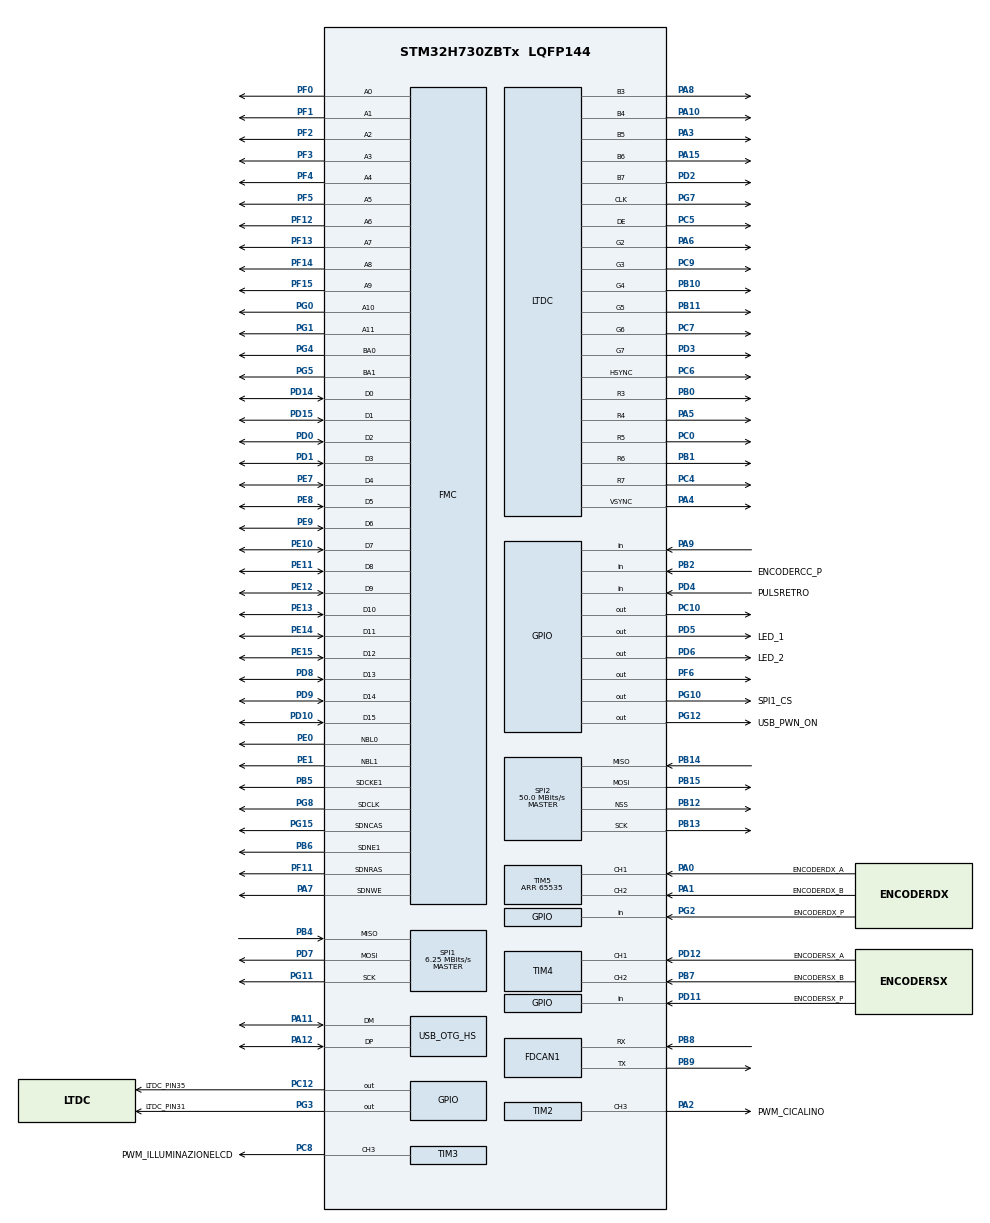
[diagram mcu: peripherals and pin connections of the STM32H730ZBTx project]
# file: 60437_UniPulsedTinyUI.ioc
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CORTEX_M7.AccessPermission-Cortex_Memory_Protection_Unit_Region1_Settings=MPU_REGION_FULL_ACCESS
CORTEX_M7.AccessPermission-Cortex_Memory_Protection_Unit_Region2_Settings=MPU_REGION_FULL_ACCESS
CORTEX_M7.BaseAddress-Cortex_Memory_Protection_Unit_Region1_Settings=0x90000000
CORTEX_M7.BaseAddress-Cortex_Memory_Protection_Unit_Region2_Settings=0xd0000000
CORTEX_M7.CPU_DCache=Enabled
CORTEX_M7.CPU_ICache=Enabled
CORTEX_M7.DisableExec-Cortex_Memory_Protection_Unit_Region1_Settings=MPU_INSTRUCTION_ACCESS_ENABLE
CORTEX_M7.DisableExec-Cortex_Memory_Protection_Unit_Region2_Settings=MPU_INSTRUCTION_ACCESS_DISABLE
CORTEX_M7.Enable-Cortex_Memory_Protection_Unit_Region0_Settings=__NULL
CORTEX_M7.Enable-Cortex_Memory_Protection_Unit_Region1_Settings=MPU_REGION_ENABLE
CORTEX_M7.Enable-Cortex_Memory_Protection_Unit_Region2_Settings=MPU_REGION_ENABLE
CORTEX_M7.IsBufferable-Cortex_Memory_Protection_Unit_Region1_Settings=MPU_ACCESS_BUFFERABLE
CORTEX_M7.IsBufferable-Cortex_Memory_Protection_Unit_Region2_Settings=MPU_ACCESS_BUFFERABLE
CORTEX_M7.IsCacheable-Cortex_Memory_Protection_Unit_Region1_Settings=MPU_ACCESS_CACHEABLE
CORTEX_M7.IsCacheable-Cortex_Memory_Protection_Unit_Region2_Settings=MPU_ACCESS_CACHEABLE
CORTEX_M7.IsShareable-Cortex_Memory_Protection_Unit_Region1_Settings=MPU_ACCESS_SHAREABLE
CORTEX_M7.MPU_Control=MPU_PRIVILEGED_DEFAULT
CORTEX_M7.Size-Cortex_Memory_Protection_Unit_Region1_Settings=MPU_REGION_SIZE_32MB
CORTEX_M7.Size-Cortex_Memory_Protection_Unit_Region2_Settings=MPU_REGION_SIZE_8MB
CORTEX_M7.default_mode_Activation=0
DMA2D.ColorMode=DMA2D_OUTPUT_RGB565
FATFS._FS_LOCK=2
FATFS._FS_NORTC=0
FATFS._USE_FIND=1
FATFS._USE_LFN=3
FATFS._USE_MKFS=0
FDCAN1.AutoRetransmission=ENABLE
FDCAN1.CalculateBaudRateNominal=125000
FDCAN1.CalculateTimeBitNominal=8000
FDCAN1.CalculateTimeQuantumNominal=500.0
FDCAN1.FrameFormat=FDCAN_FRAME_CLASSIC
FDCAN1.NominalPrescaler=50
FDCAN1.NominalTimeSeg1=13
FDCAN1.RxBuffersNbr=16
FDCAN1.RxFifo0ElmtsNbr=16
FDCAN1.RxFifo1ElmtsNbr=0
FDCAN1.StdFiltersNbr=1
FDCAN1.TxFifoQueueElmtsNbr=16
FMC.CASLatency2=FMC_SDRAM_CAS_LATENCY_3
FMC.ExitSelfRefreshDelay2=14
FMC.LoadToActiveDelay2=2
FMC.RCDDelay2=3
FMC.RPDelay2=3
FMC.ReadBurst2=FMC_SDRAM_RBURST_ENABLE
FMC.ReadPipeDelay2=FMC_SDRAM_RPIPE_DELAY_1
FMC.RowCycleDelay2=11
FMC.SDClockPeriod2=FMC_SDRAM_CLOCK_PERIOD_2
FMC.SelfRefreshTime2=8
FMC.WriteRecoveryTime2=5
FREERTOS.Tasks01=defaultTask,24,512,StartDefaultTask,Default,NULL,Dynamic,NULL,NULL
FREERTOS.configCHECK_FOR_STACK_OVERFLOW=2
FREERTOS.configENABLE_FPU=1
FREERTOS.configQUEUE_REGISTRY_SIZE=16
FREERTOS.configRECORD_STACK_HIGH_ADDRESS=1
FREERTOS.configTIMER_QUEUE_LENGTH=15
FREERTOS.configTOTAL_HEAP_SIZE=120000
FREERTOS.configUSE_APPLICATION_TASK_TAG=1
FREERTOS.configUSE_IDLE_HOOK=1
FREERTOS.configUSE_NEWLIB_REENTRANT=1
LTDC.ActiveH=272
LTDC.ActiveW=480
LTDC.Alpha_L0=255
LTDC.HBP=88
LTDC.HFP=40
LTDC.HSync=48
LTDC.ImageHeight_L0=272
LTDC.ImageWidth_L0=480
LTDC.Layers=0
LTDC.PixelFormat_L0=LTDC_PIXEL_FORMAT_RGB565
LTDC.VBP=32
LTDC.VFP=13
LTDC.VSync=3
LTDC.WindowX1_L0=480
LTDC.WindowY1_L0=272
Mcu.Family=STM32H7
Mcu.Name=STM32H730ZBTx
Mcu.Package=LQFP144
NVIC.DMA2D_IRQn=true\:5\:0\:false\:false\:true\:true\:true\:true\:true
NVIC.FDCAN1_IT0_IRQn=true\:5\:0\:false\:false\:true\:true\:true\:true\:true
NVIC.FDCAN1_IT1_IRQn=true\:5\:0\:false\:false\:true\:true\:true\:true\:true
NVIC.LTDC_IRQn=true\:5\:0\:false\:false\:true\:true\:true\:true\:true
NVIC.OTG_HS_IRQn=true\:5\:0\:false\:false\:true\:true\:false\:true\:true
NVIC.PriorityGroup=NVIC_PRIORITYGROUP_4
NVIC.TIM6_DAC_IRQn=true\:15\:0\:false\:false\:true\:false\:false\:true\:true
NVIC.TimeBase=TIM6_DAC_IRQn
NVIC.TimeBaseIP=TIM6
PA0.GPIO_Label=ENCODERDX_A
PA0.Signal=S_TIM5_CH1
PA1.GPIO_Label=ENCODERDX_B
PA1.Signal=S_TIM5_CH2
PA10.Mode=RGB565
PA10.Signal=LTDC_B4
PA11.Mode=Host_FS
PA11.Signal=USB_OTG_HS_DM
PA12.Mode=Host_FS
PA12.Signal=USB_OTG_HS_DP
PA13(JTMS/SWDIO).Mode=Trace_Asynchronous_SW
PA13(JTMS/SWDIO).Signal=DEBUG_JTMS-SWDIO
PA14(JTCK/SWCLK).Mode=Trace_Asynchronous_SW
PA14(JTCK/SWCLK).Signal=DEBUG_JTCK-SWCLK
PA15(JTDI).Mode=RGB565
PA15(JTDI).Signal=LTDC_B6
PA2.GPIO_Label=PWM_CICALINO
PA2.Signal=S_TIM2_CH3
PA3.Mode=RGB565
PA3.Signal=LTDC_B5
PA4.Mode=RGB565
PA4.Signal=LTDC_VSYNC
PA5.Mode=RGB565
PA5.Signal=LTDC_R4
PA6.Mode=RGB565
PA6.Signal=LTDC_G2
PA7.Signal=FMC_SDNWE
PA8.Mode=RGB565
PA8.Signal=LTDC_B3
PA9.Signal=GPIO_Input
PB0.Mode=RGB565
PB0.Signal=LTDC_R3
PB1.Mode=RGB565
PB1.Signal=LTDC_R6
PB10.Mode=RGB565
PB10.Signal=LTDC_G4
PB11.Mode=RGB565
PB11.Signal=LTDC_G5
PB12.Mode=NSS_Signal_Hard_Output
PB12.Signal=SPI2_NSS
PB13.Mode=Full_Duplex_Master
PB13.Signal=SPI2_SCK
PB14.Mode=Full_Duplex_Master
PB14.Signal=SPI2_MISO
PB15.Mode=Full_Duplex_Master
PB15.Signal=SPI2_MOSI
PB2.GPIO_Label=ENCODERCC_P
PB2.Signal=GPIO_Input
PB3(JTDO/TRACESWO).Mode=Trace_Asynchronous_SW
PB3(JTDO/TRACESWO).Signal=DEBUG_JTDO-SWO
PB4(NJTRST).Mode=Full_Duplex_Master
PB4(NJTRST).Signal=SPI1_MISO
PB5.Mode=SdramChipSelect2_2
PB5.Signal=FMC_SDCKE1
PB6.Mode=SdramChipSelect2_2
PB6.Signal=FMC_SDNE1
PB7.GPIO_Label=ENCODERSX_B
PB7.Signal=S_TIM4_CH2
PB8.Mode=FDCAN_Activate
PB8.Signal=FDCAN1_RX
PB9.Mode=FDCAN_Activate
PB9.Signal=FDCAN1_TX
PC0.Mode=RGB565
PC0.Signal=LTDC_R5
PC10.Signal=GPIO_Output
PC12.GPIO_Label=LTDC_PIN35
PC12.Signal=GPIO_Output
PC14-OSC32_IN.Mode=LSE-External-Oscillator
PC14-OSC32_IN.Signal=RCC_OSC32_IN
PC15-OSC32_OUT.Mode=LSE-External-Oscillator
PC15-OSC32_OUT.Signal=RCC_OSC32_OUT
PC4.Mode=RGB565
PC4.Signal=LTDC_R7
PC5.Mode=RGB565
PC5.Signal=LTDC_DE
PC6.Mode=RGB565
PC6.Signal=LTDC_HSYNC
PC7.Mode=RGB565
PC7.Signal=LTDC_G6
PC8.GPIO_Label=PWM_ILLUMINAZIONELCD
PC8.Signal=S_TIM3_CH3
PC9.Mode=RGB565
PC9.Signal=LTDC_G3
PD0.Signal=FMC_D2_DA2
PD1.Signal=FMC_D3_DA3
PD10.Signal=FMC_D15_DA15
PD11.GPIO_Label=ENCODERSX_P
PD11.Signal=GPIO_Input
PD12.GPIO_Label=ENCODERSX_A
PD12.Signal=S_TIM4_CH1
PD14.Signal=FMC_D0_DA0
PD15.Signal=FMC_D1_DA1
PD2.Mode=RGB565
PD2.Signal=LTDC_B7
PD3.Mode=RGB565
PD3.Signal=LTDC_G7
PD4.GPIO_Label=PULSRETRO
PD4.Signal=GPIO_Input
PD5.GPIO_Label=LED_1
PD5.Signal=GPIO_Output
PD6.GPIO_Label=LED_2
PD6.Signal=GPIO_Output
PD7.Mode=Full_Duplex_Master
PD7.Signal=SPI1_MOSI
PD8.Signal=FMC_D13_DA13
PD9.Signal=FMC_D14_DA14
PE0.Signal=FMC_NBL0
PE1.Signal=FMC_NBL1
PE10.Signal=FMC_D7_DA7
PE11.Signal=FMC_D8_DA8
PE12.Signal=FMC_D9_DA9
PE13.Signal=FMC_D10_DA10
PE14.Signal=FMC_D11_DA11
PE15.Signal=FMC_D12_DA12
PE7.Signal=FMC_D4_DA4
PE8.Signal=FMC_D5_DA5
PE9.Signal=FMC_D6_DA6
PF0.Signal=FMC_A0
PF1.Signal=FMC_A1
PF11.Signal=FMC_SDNRAS
PF12.Signal=FMC_A6
PF13.Signal=FMC_A7
PF14.Signal=FMC_A8
PF15.Signal=FMC_A9
PF2.Signal=FMC_A2
PF3.Signal=FMC_A3
PF4.Signal=FMC_A4
PF5.Signal=FMC_A5
PF6.Signal=GPIO_Output
PF7.Signal=OCTOSPIM_P1_IO2
PG0.Signal=FMC_A10
PG1.Signal=FMC_A11
PG10.GPIO_Label=SPI1_CS
PG10.GPIO_ModeDefaultOutputPP=GPIO_MODE_OUTPUT_OD
PG10.GPIO_PuPd=GPIO_NOPULL
PG10.PinState=GPIO_PIN_SET
PG10.Signal=GPIO_Output
PG11.Mode=Full_Duplex_Master
PG11.Signal=SPI1_SCK
PG12.GPIO_Label=USB_PWN_ON
PG12.GPIO_ModeDefaultOutputPP=GPIO_MODE_OUTPUT_OD
PG12.GPIO_PuPd=GPIO_NOPULL
PG12.PinState=GPIO_PIN_SET
PG12.Signal=GPIO_Output
PG15.Signal=FMC_SDNCAS
PG2.GPIO_Label=ENCODERDX_P
PG2.Signal=GPIO_Input
PG3.GPIO_Label=LTDC_PIN31
PG3.Signal=GPIO_Output
PG4.Signal=FMC_A14_BA0
PG5.Signal=FMC_A15_BA1
PG7.Mode=RGB565
PG7.Signal=LTDC_CLK
PG8.Signal=FMC_SDCLK
PH0-OSC_IN.Mode=HSE-External-Oscillator
PH0-OSC_IN.Signal=RCC_OSC_IN
PH1-OSC_OUT.Mode=HSE-External-Oscillator
PH1-OSC_OUT.Signal=RCC_OSC_OUT
ProjectManager.HeapSize=0x00
ProjectManager.StackSize=0x4000
ProjectManager.TargetToolchain=STM32CubeIDE
RCC.ADCFreq_Value=100000000
RCC.APB1Freq_Value=137500000
RCC.APB2Freq_Value=137500000
RCC.APB3Freq_Value=137500000
RCC.APB4Freq_Value=137500000
RCC.CortexFreq_Value=550000000
RCC.D1PPRE=RCC_APB3_DIV2
RCC.D2PPRE1=RCC_APB1_DIV2
RCC.D2PPRE2=RCC_APB2_DIV2
RCC.D3PPRE=RCC_APB4_DIV2
RCC.DIVM1=8
RCC.DIVM2=8
RCC.DIVM3=16
RCC.DIVN1=275
RCC.DIVN2=100
RCC.DIVN3=30
RCC.DIVP1=1
RCC.DIVR2=1
RCC.DIVR3=3
RCC.FDCANCLockSelection=RCC_FDCANCLKSOURCE_PLL2
RCC.HCLKFreq_Value=275000000
RCC.HPRE=RCC_HCLK_DIV2
RCC.HSE_VALUE=16000000
RCC.PLLSourceVirtual=RCC_PLLSOURCE_HSE
RCC.RTCClockSelection=RCC_RTCCLKSOURCE_LSE
RCC.SPI123CLockSelection=RCC_SPI123CLKSOURCE_PLL2
RCC.SYSCLKFreq_VALUE=550000000
RCC.SYSCLKSource=RCC_SYSCLKSOURCE_PLLCLK
RCC.USBCLockSelection=RCC_USBCLKSOURCE_HSI48
RCC.USBFreq_Value=48000000
SH.FMC_A0.0=FMC_A0,12b-sda2
SH.FMC_A1.0=FMC_A1,12b-sda2
SH.FMC_A10.0=FMC_A10,12b-sda2
SH.FMC_A11.0=FMC_A11,12b-sda2
SH.FMC_A14_BA0.0=FMC_BA0,FourSdramBanks2
SH.FMC_A15_BA1.0=FMC_BA1,FourSdramBanks2
SH.FMC_A2.0=FMC_A2,12b-sda2
SH.FMC_A3.0=FMC_A3,12b-sda2
SH.FMC_A4.0=FMC_A4,12b-sda2
SH.FMC_A5.0=FMC_A5,12b-sda2
SH.FMC_A6.0=FMC_A6,12b-sda2
SH.FMC_A7.0=FMC_A7,12b-sda2
SH.FMC_A8.0=FMC_A8,12b-sda2
SH.FMC_A9.0=FMC_A9,12b-sda2
SH.FMC_D0_DA0.0=FMC_D0,sd-16b-d2
SH.FMC_D10_DA10.0=FMC_D10,sd-16b-d2
SH.FMC_D11_DA11.0=FMC_D11,sd-16b-d2
SH.FMC_D12_DA12.0=FMC_D12,sd-16b-d2
SH.FMC_D13_DA13.0=FMC_D13,sd-16b-d2
SH.FMC_D14_DA14.0=FMC_D14,sd-16b-d2
SH.FMC_D15_DA15.0=FMC_D15,sd-16b-d2
SH.FMC_D1_DA1.0=FMC_D1,sd-16b-d2
SH.FMC_D2_DA2.0=FMC_D2,sd-16b-d2
SH.FMC_D3_DA3.0=FMC_D3,sd-16b-d2
SH.FMC_D4_DA4.0=FMC_D4,sd-16b-d2
SH.FMC_D5_DA5.0=FMC_D5,sd-16b-d2
SH.FMC_D6_DA6.0=FMC_D6,sd-16b-d2
SH.FMC_D7_DA7.0=FMC_D7,sd-16b-d2
SH.FMC_D8_DA8.0=FMC_D8,sd-16b-d2
SH.FMC_D9_DA9.0=FMC_D9,sd-16b-d2
SH.FMC_NBL0.0=FMC_NBL0,Sd2ByteEnable2
SH.FMC_NBL1.0=FMC_NBL1,Sd2ByteEnable2
SH.FMC_SDCLK.0=FMC_SDCLK,12b-sda2
SH.FMC_SDNCAS.0=FMC_SDNCAS,12b-sda2
SH.FMC_SDNRAS.0=FMC_SDNRAS,12b-sda2
SH.FMC_SDNWE.0=FMC_SDNWE,12b-sda2
SH.S_TIM2_CH3.0=TIM2_CH3,PWM Generation3 CH3
SH.S_TIM3_CH3.0=TIM3_CH3,PWM Generation3 CH3
SH.S_TIM4_CH1.0=TIM4_CH1,Encoder_Interface
SH.S_TIM4_CH2.0=TIM4_CH2,Encoder_Interface
SH.S_TIM5_CH1.0=TIM5_CH1,Encoder_Interface
SH.S_TIM5_CH2.0=TIM5_CH2,Encoder_Interface
SPI1.BaudRatePrescaler=SPI_BAUDRATEPRESCALER_16
SPI1.CalculateBaudRate=6.25 MBits/s
SPI1.DataSize=SPI_DATASIZE_8BIT
SPI1.Direction=SPI_DIRECTION_2LINES
SPI1.Mode=SPI_MODE_MASTER
SPI1.VirtualType=VM_MASTER
SPI2.BaudRatePrescaler=SPI_BAUDRATEPRESCALER_2
SPI2.CalculateBaudRate=50.0 MBits/s
SPI2.Direction=SPI_DIRECTION_2LINES
SPI2.Mode=SPI_MODE_MASTER
SPI2.VirtualNSS=VM_NSSHARD
SPI2.VirtualType=VM_MASTER
STMicroelectronics.X-CUBE-TOUCHGFX.4.24.1.ApplicationCcGraphicsJjApplication=TouchGFXOoGenerator
STMicroelectronics.X-CUBE-TOUCHGFX.4.24.1.tgfx_address1=0xd0000000
STMicroelectronics.X-CUBE-TOUCHGFX.4.24.1.tgfx_address2=0xd003fc00
STMicroelectronics.X-CUBE-TOUCHGFX.4.24.1.tgfx_buffering_strategy=Double
STMicroelectronics.X-CUBE-TOUCHGFX.4.24.1.tgfx_display_interface=disp_ltdc
STMicroelectronics.X-CUBE-TOUCHGFX.4.24.1.tgfx_hardware_accelerator=dma_2d
STMicroelectronics.X-CUBE-TOUCHGFX.4.24.1.tgfx_location=By Address
STMicroelectronics.X-CUBE-TOUCHGFX.4.24.1.tgfx_vsync=vsync_ltdc
STMicroelectronics.X-CUBE-TOUCHGFX.4.24.1_IsPackSelfContextualization=true
TIM2.Channel-PWM\ Generation3\ CH3=TIM_CHANNEL_3
TIM2.Period=1000
TIM2.Prescaler=68
TIM2.Pulse-PWM\ Generation3\ CH3=500
TIM3.AutoReloadPreload=TIM_AUTORELOAD_PRELOAD_ENABLE
TIM3.Channel-PWM\ Generation3\ CH3=TIM_CHANNEL_3
TIM3.ClockDivision=TIM_CLOCKDIVISION_DIV4
TIM3.OCFastMode_PWM-PWM\ Generation3\ CH3=TIM_OCFAST_DISABLE
TIM3.Period=1000
TIM3.Prescaler=5
TIM3.Pulse-PWM\ Generation3\ CH3=5000
TIM4.IC1Polarity=TIM_ICPOLARITY_RISING
TIM4.IC2Polarity=TIM_ICPOLARITY_RISING
TIM5.IC1Polarity=TIM_ICPOLARITY_RISING
TIM5.IC2Polarity=TIM_ICPOLARITY_RISING
TIM5.Period=65535
USB_HOST.BSP.number=1
USB_HOST.USBH_DEBUG_LEVEL=3
USB_HOST.USBH_HandleTypeDef=hUsbHostHS
USB_HOST.USBH_PROCESS_STACK_SIZE=512
USB_HOST.VirtualModeHS=Msc
USB_HOST0.BSP.STBoard=false
USB_HOST0.BSP.api=Unknown
USB_HOST0.BSP.instance=PG12
USB_HOST0.BSP.ip=GPIO
USB_HOST0.BSP.mode=Output
USB_HOST0.BSP.name=Drive_VBUS_HS
USB_HOST0.BSP.solution=PG12
USB_OTG_HS.VirtualMode-Host_FS=Host_FS
VP_CRC_VS_CRC.Mode=CRC_Activate
VP_DMA2D_VS_DMA2D.Mode=DMA2D_Activate
VP_FATFS_VS_USB.Mode=USB
VP_FREERTOS_VS_CMSIS_V2.Mode=CMSIS_V2
VP_RTC_VS_RTC_Activate.Mode=RTC_Enabled
VP_STMicroelectronics.X-CUBE-TOUCHGFX_VS_GraphicsJjApplication_4.24.1.Mode=GraphicsJjApplication
VP_SYS_VS_tim6.Mode=TIM6
VP_USB_HOST_VS_USB_HOST_MSC_HS.Mode=MSC_HS
board=custom

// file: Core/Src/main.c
/* USER CODE BEGIN Header */
/**
  ******************************************************************************
  * @file           : main.c
  * @brief          : Main program body
  ******************************************************************************
  * @attention
  *
  * Copyright (c) 2023 STMicroelectronics.
  * All rights reserved.
  *
  * This software is licensed under terms that can be found in the LICENSE file
  * in the root directory of this software component.
  * If no LICENSE file comes with this software, it is provided AS-IS.
  *
  ******************************************************************************
  */
/* USER CODE END Header */
#include "main.h"
#include "cmsis_os.h"
#include "fatfs.h"
#include "app_touchgfx.h"
#include "usb_host.h"

/* USER CODE BEGIN Includes */
#include "ARMLib/Device/SDRAM/_SDRAM.h"
#include "_Board.h"
#include "ARMLib/Common/SwTimer.h"
#include "Applicazione.h"
/* USER CODE END Includes */

CRC_HandleTypeDef hcrc;

DMA2D_HandleTypeDef hdma2d;

FDCAN_HandleTypeDef hfdcan1;

LTDC_HandleTypeDef hltdc;

RTC_HandleTypeDef hrtc;

SPI_HandleTypeDef hspi1;
SPI_HandleTypeDef hspi2;

TIM_HandleTypeDef htim2;
TIM_HandleTypeDef htim3;
TIM_HandleTypeDef htim4;
TIM_HandleTypeDef htim5;

SDRAM_HandleTypeDef hsdram2;

/* Definitions for defaultTask */
osThreadId_t defaultTaskHandle;
const osThreadAttr_t defaultTask_attributes = {
  .name = "defaultTask",
  .stack_size = 512 * 4,
  .priority = (osPriority_t) osPriorityNormal,
};
/* USER CODE BEGIN PV */
void TouchGFX_Task(void *argument);
osThreadId_t GUITaskHandle;
const osThreadAttr_t GUITask_attributes = {
	.name = "GUITask",
	.stack_size = 16384 * 4,
	.priority = (osPriority_t) osPriorityBelowNormal,
};

/* USER CODE END PV */

void SystemClock_Config(void);
void PeriphCommonClock_Config(void);
static void MPU_Config(void);
static void MX_GPIO_Init(void);
static void MX_FMC_Init(void);
static void MX_LTDC_Init(void);
static void MX_DMA2D_Init(void);
static void MX_FDCAN1_Init(void);
static void MX_SPI1_Init(void);
static void MX_CRC_Init(void);
static void MX_TIM3_Init(void);
static void MX_TIM4_Init(void);
static void MX_TIM5_Init(void);
static void MX_SPI2_Init(void);
static void MX_TIM2_Init(void);
static void MX_RTC_Init(void);
void StartDefaultTask(void *argument);

int main(void)
{

  /* USER CODE BEGIN 1 */
	SCB->VTOR = _BOARD_ADDRESSFIRMWARE;	// NOTA: i +H200 è l'offset per le info aggiornamenti e versioning condificati
	__enable_irq();
  /* USER CODE END 1 */

  /* MPU Configuration--------------------------------------------------------*/
  MPU_Config();

  /* Enable the CPU Cache */

  /* Enable I-Cache---------------------------------------------------------*/
  SCB_EnableICache();

  /* Enable D-Cache---------------------------------------------------------*/
  SCB_EnableDCache();

  /* MCU Configuration--------------------------------------------------------*/

  /* Reset of all peripherals, Initializes the Flash interface and the Systick. */
  HAL_Init();

  /* Configure the system clock */
  SystemClock_Config();

/* Configure the peripherals common clocks */
  PeriphCommonClock_Config();

  /* USER CODE BEGIN SysInit */
	// Attiva il backup system e parametri VBat
	__HAL_RCC_BKPRAM_CLK_ENABLE();

	HAL_PWREx_DisableBatteryCharging();
	HAL_PWREx_EnableBkUpReg();
	HAL_PWR_EnableBkUpAccess();

	/* Enable Back up SRAM */
	/* Enable write access to Backup domain */

	PWR->CR1 |= PWR_CR1_DBP;

	while((PWR->CR1 & PWR_CR1_DBP) == RESET)
	{
	}
  /* USER CODE END SysInit */

  /* Initialize all configured peripherals */
  MX_GPIO_Init();
  MX_FMC_Init();
  MX_LTDC_Init();
  MX_DMA2D_Init();
  MX_FDCAN1_Init();
  MX_SPI1_Init();
  MX_CRC_Init();
  MX_TIM3_Init();
  MX_TIM4_Init();
  MX_TIM5_Init();
  MX_SPI2_Init();
  MX_TIM2_Init();
  MX_RTC_Init();
  MX_FATFS_Init();
  MX_TouchGFX_Init();
  /* Call PreOsInit function */
  MX_TouchGFX_PreOSInit();

  /* Init scheduler */
  osKernelInitialize();

  /* Create the thread(s) */
  /* creation of defaultTask */
  defaultTaskHandle = osThreadNew(StartDefaultTask, NULL, &defaultTask_attributes);

  /* USER CODE BEGIN RTOS_THREADS */

  if(applicazione_InitModule()!=_STATUS_OK_)
  {
	  while(1);
  }

  GUITaskHandle = osThreadNew(TouchGFX_Task, NULL, &GUITask_attributes);

  /* add threads, ... */
  /* USER CODE END RTOS_THREADS */

  /* Start scheduler */
  osKernelStart();

  /* We should never get here as control is now taken by the scheduler */

  /* Infinite loop */
  while (1)
  {

  }
}

void SystemClock_Config(void)
{
  RCC_OscInitTypeDef RCC_OscInitStruct = {0};
  RCC_ClkInitTypeDef RCC_ClkInitStruct = {0};

  /** Supply configuration update enable
  */
  HAL_PWREx_ConfigSupply(PWR_LDO_SUPPLY);

  /** Configure the main internal regulator output voltage
  */
  __HAL_PWR_VOLTAGESCALING_CONFIG(PWR_REGULATOR_VOLTAGE_SCALE0);

  while(!__HAL_PWR_GET_FLAG(PWR_FLAG_VOSRDY)) {}

  /** Configure LSE Drive Capability
  */
  HAL_PWR_EnableBkUpAccess();
  __HAL_RCC_LSEDRIVE_CONFIG(RCC_LSEDRIVE_LOW);

  /** Initializes the RCC Oscillators according to the specified parameters
  * in the RCC_OscInitTypeDef structure.
  */
  RCC_OscInitStruct.OscillatorType = RCC_OSCILLATORTYPE_HSI48|RCC_OSCILLATORTYPE_HSE
                              |RCC_OSCILLATORTYPE_LSE;
  RCC_OscInitStruct.HSEState = RCC_HSE_ON;
  RCC_OscInitStruct.LSEState = RCC_LSE_ON;
  RCC_OscInitStruct.HSI48State = RCC_HSI48_ON;
  RCC_OscInitStruct.PLL.PLLState = RCC_PLL_ON;
  RCC_OscInitStruct.PLL.PLLSource = RCC_PLLSOURCE_HSE;
  RCC_OscInitStruct.PLL.PLLM = 8;
  RCC_OscInitStruct.PLL.PLLN = 275;
  RCC_OscInitStruct.PLL.PLLP = 1;
  RCC_OscInitStruct.PLL.PLLQ = 2;
  RCC_OscInitStruct.PLL.PLLR = 2;
  RCC_OscInitStruct.PLL.PLLRGE = RCC_PLL1VCIRANGE_1;
  RCC_OscInitStruct.PLL.PLLVCOSEL = RCC_PLL1VCOWIDE;
  RCC_OscInitStruct.PLL.PLLFRACN = 0;
  if (HAL_RCC_OscConfig(&RCC_OscInitStruct) != HAL_OK)
  {
    Error_Handler();
  }

  /** Initializes the CPU, AHB and APB buses clocks
  */
  RCC_ClkInitStruct.ClockType = RCC_CLOCKTYPE_HCLK|RCC_CLOCKTYPE_SYSCLK
                              |RCC_CLOCKTYPE_PCLK1|RCC_CLOCKTYPE_PCLK2
                              |RCC_CLOCKTYPE_D3PCLK1|RCC_CLOCKTYPE_D1PCLK1;
  RCC_ClkInitStruct.SYSCLKSource = RCC_SYSCLKSOURCE_PLLCLK;
  RCC_ClkInitStruct.SYSCLKDivider = RCC_SYSCLK_DIV1;
  RCC_ClkInitStruct.AHBCLKDivider = RCC_HCLK_DIV2;
  RCC_ClkInitStruct.APB3CLKDivider = RCC_APB3_DIV2;
  RCC_ClkInitStruct.APB1CLKDivider = RCC_APB1_DIV2;
  RCC_ClkInitStruct.APB2CLKDivider = RCC_APB2_DIV2;
  RCC_ClkInitStruct.APB4CLKDivider = RCC_APB4_DIV2;

  if (HAL_RCC_ClockConfig(&RCC_ClkInitStruct, FLASH_LATENCY_3) != HAL_OK)
  {
    Error_Handler();
  }
}

void PeriphCommonClock_Config(void)
{
  RCC_PeriphCLKInitTypeDef PeriphClkInitStruct = {0};

  /** Initializes the peripherals clock
  */
  PeriphClkInitStruct.PeriphClockSelection = RCC_PERIPHCLK_SPI2|RCC_PERIPHCLK_SPI1
                              |RCC_PERIPHCLK_FDCAN;
  PeriphClkInitStruct.PLL2.PLL2M = 8;
  PeriphClkInitStruct.PLL2.PLL2N = 100;
  PeriphClkInitStruct.PLL2.PLL2P = 2;
  PeriphClkInitStruct.PLL2.PLL2Q = 2;
  PeriphClkInitStruct.PLL2.PLL2R = 1;
  PeriphClkInitStruct.PLL2.PLL2RGE = RCC_PLL2VCIRANGE_1;
  PeriphClkInitStruct.PLL2.PLL2VCOSEL = RCC_PLL2VCOWIDE;
  PeriphClkInitStruct.PLL2.PLL2FRACN = 0;
  PeriphClkInitStruct.Spi123ClockSelection = RCC_SPI123CLKSOURCE_PLL2;
  PeriphClkInitStruct.FdcanClockSelection = RCC_FDCANCLKSOURCE_PLL2;
  if (HAL_RCCEx_PeriphCLKConfig(&PeriphClkInitStruct) != HAL_OK)
  {
    Error_Handler();
  }
}

static void MX_CRC_Init(void)
{

  hcrc.Instance = CRC;
  hcrc.Init.DefaultPolynomialUse = DEFAULT_POLYNOMIAL_ENABLE;
  hcrc.Init.DefaultInitValueUse = DEFAULT_INIT_VALUE_ENABLE;
  hcrc.Init.InputDataInversionMode = CRC_INPUTDATA_INVERSION_NONE;
  hcrc.Init.OutputDataInversionMode = CRC_OUTPUTDATA_INVERSION_DISABLE;
  hcrc.InputDataFormat = CRC_INPUTDATA_FORMAT_BYTES;
  if (HAL_CRC_Init(&hcrc) != HAL_OK)
  {
    Error_Handler();
  }

}

static void MX_DMA2D_Init(void)
{

  hdma2d.Instance = DMA2D;
  hdma2d.Init.Mode = DMA2D_M2M;
  hdma2d.Init.ColorMode = DMA2D_OUTPUT_RGB565;
  hdma2d.Init.OutputOffset = 0;
  hdma2d.LayerCfg[1].InputOffset = 0;
  hdma2d.LayerCfg[1].InputColorMode = DMA2D_INPUT_RGB565;
  hdma2d.LayerCfg[1].AlphaMode = DMA2D_NO_MODIF_ALPHA;
  hdma2d.LayerCfg[1].InputAlpha = 0;
  hdma2d.LayerCfg[1].AlphaInverted = DMA2D_REGULAR_ALPHA;
  hdma2d.LayerCfg[1].RedBlueSwap = DMA2D_RB_REGULAR;
  hdma2d.LayerCfg[1].ChromaSubSampling = DMA2D_NO_CSS;
  if (HAL_DMA2D_Init(&hdma2d) != HAL_OK)
  {
    Error_Handler();
  }
  if (HAL_DMA2D_ConfigLayer(&hdma2d, 1) != HAL_OK)
  {
    Error_Handler();
  }

}

static void MX_FDCAN1_Init(void)
{

  hfdcan1.Instance = FDCAN1;
  hfdcan1.Init.FrameFormat = FDCAN_FRAME_CLASSIC;
  hfdcan1.Init.Mode = FDCAN_MODE_NORMAL;
  hfdcan1.Init.AutoRetransmission = ENABLE;
  hfdcan1.Init.TransmitPause = DISABLE;
  hfdcan1.Init.ProtocolException = DISABLE;
  hfdcan1.Init.NominalPrescaler = 50;
  hfdcan1.Init.NominalSyncJumpWidth = 1;
  hfdcan1.Init.NominalTimeSeg1 = 13;
  hfdcan1.Init.NominalTimeSeg2 = 2;
  hfdcan1.Init.DataPrescaler = 1;
  hfdcan1.Init.DataSyncJumpWidth = 1;
  hfdcan1.Init.DataTimeSeg1 = 1;
  hfdcan1.Init.DataTimeSeg2 = 1;
  hfdcan1.Init.MessageRAMOffset = 0;
  hfdcan1.Init.StdFiltersNbr = 1;
  hfdcan1.Init.ExtFiltersNbr = 0;
  hfdcan1.Init.RxFifo0ElmtsNbr = 16;
  hfdcan1.Init.RxFifo0ElmtSize = FDCAN_DATA_BYTES_8;
  hfdcan1.Init.RxFifo1ElmtsNbr = 0;
  hfdcan1.Init.RxFifo1ElmtSize = FDCAN_DATA_BYTES_8;
  hfdcan1.Init.RxBuffersNbr = 16;
  hfdcan1.Init.RxBufferSize = FDCAN_DATA_BYTES_8;
  hfdcan1.Init.TxEventsNbr = 0;
  hfdcan1.Init.TxBuffersNbr = 0;
  hfdcan1.Init.TxFifoQueueElmtsNbr = 16;
  hfdcan1.Init.TxFifoQueueMode = FDCAN_TX_FIFO_OPERATION;
  hfdcan1.Init.TxElmtSize = FDCAN_DATA_BYTES_8;
  if (HAL_FDCAN_Init(&hfdcan1) != HAL_OK)
  {
    Error_Handler();
  }

}

static void MX_LTDC_Init(void)
{

  LTDC_LayerCfgTypeDef pLayerCfg = {0};

  hltdc.Instance = LTDC;
  hltdc.Init.HSPolarity = LTDC_HSPOLARITY_AL;
  hltdc.Init.VSPolarity = LTDC_VSPOLARITY_AL;
  hltdc.Init.DEPolarity = LTDC_DEPOLARITY_AL;
  hltdc.Init.PCPolarity = LTDC_PCPOLARITY_IPC;
  hltdc.Init.HorizontalSync = 47;
  hltdc.Init.VerticalSync = 2;
  hltdc.Init.AccumulatedHBP = 135;
  hltdc.Init.AccumulatedVBP = 34;
  hltdc.Init.AccumulatedActiveW = 615;
  hltdc.Init.AccumulatedActiveH = 306;
  hltdc.Init.TotalWidth = 655;
  hltdc.Init.TotalHeigh = 319;
  hltdc.Init.Backcolor.Blue = 0;
  hltdc.Init.Backcolor.Green = 0;
  hltdc.Init.Backcolor.Red = 0;
  if (HAL_LTDC_Init(&hltdc) != HAL_OK)
  {
    Error_Handler();
  }
  pLayerCfg.WindowX0 = 0;
  pLayerCfg.WindowX1 = 480;
  pLayerCfg.WindowY0 = 0;
  pLayerCfg.WindowY1 = 272;
  pLayerCfg.PixelFormat = LTDC_PIXEL_FORMAT_RGB565;
  pLayerCfg.Alpha = 255;
  pLayerCfg.Alpha0 = 0;
  pLayerCfg.BlendingFactor1 = LTDC_BLENDING_FACTOR1_CA;
  pLayerCfg.BlendingFactor2 = LTDC_BLENDING_FACTOR2_CA;
  pLayerCfg.FBStartAdress = 0;
  pLayerCfg.ImageWidth = 480;
  pLayerCfg.ImageHeight = 272;
  pLayerCfg.Backcolor.Blue = 0;
  pLayerCfg.Backcolor.Green = 0;
  pLayerCfg.Backcolor.Red = 0;
  if (HAL_LTDC_ConfigLayer(&hltdc, &pLayerCfg, 0) != HAL_OK)
  {
    Error_Handler();
  }
  /* USER CODE BEGIN LTDC_Init 2 */

  	  HAL_LTDC_SetAddress(&hltdc,_BOARD_LCD_FRAMEBUFFERADDRESS,0);
  /* USER CODE END LTDC_Init 2 */

}

static void MX_RTC_Init(void)
{

  /** Initialize RTC Only
  */
  hrtc.Instance = RTC;
  hrtc.Init.HourFormat = RTC_HOURFORMAT_24;
  hrtc.Init.AsynchPrediv = 127;
  hrtc.Init.SynchPrediv = 255;
  hrtc.Init.OutPut = RTC_OUTPUT_DISABLE;
  hrtc.Init.OutPutPolarity = RTC_OUTPUT_POLARITY_HIGH;
  hrtc.Init.OutPutType = RTC_OUTPUT_TYPE_OPENDRAIN;
  hrtc.Init.OutPutRemap = RTC_OUTPUT_REMAP_NONE;
  if (HAL_RTC_Init(&hrtc) != HAL_OK)
  {
    Error_Handler();
  }

}

static void MX_SPI1_Init(void)
{

  /* SPI1 parameter configuration*/
  hspi1.Instance = SPI1;
  hspi1.Init.Mode = SPI_MODE_MASTER;
  hspi1.Init.Direction = SPI_DIRECTION_2LINES;
  hspi1.Init.DataSize = SPI_DATASIZE_8BIT;
  hspi1.Init.CLKPolarity = SPI_POLARITY_LOW;
  hspi1.Init.CLKPhase = SPI_PHASE_1EDGE;
  hspi1.Init.NSS = SPI_NSS_SOFT;
  hspi1.Init.BaudRatePrescaler = SPI_BAUDRATEPRESCALER_16;
  hspi1.Init.FirstBit = SPI_FIRSTBIT_MSB;
  hspi1.Init.TIMode = SPI_TIMODE_DISABLE;
  hspi1.Init.CRCCalculation = SPI_CRCCALCULATION_DISABLE;
  hspi1.Init.CRCPolynomial = 0x0;
  hspi1.Init.NSSPMode = SPI_NSS_PULSE_ENABLE;
  hspi1.Init.NSSPolarity = SPI_NSS_POLARITY_LOW;
  hspi1.Init.FifoThreshold = SPI_FIFO_THRESHOLD_01DATA;
  hspi1.Init.TxCRCInitializationPattern = SPI_CRC_INITIALIZATION_ALL_ZERO_PATTERN;
  hspi1.Init.RxCRCInitializationPattern = SPI_CRC_INITIALIZATION_ALL_ZERO_PATTERN;
  hspi1.Init.MasterSSIdleness = SPI_MASTER_SS_IDLENESS_00CYCLE;
  hspi1.Init.MasterInterDataIdleness = SPI_MASTER_INTERDATA_IDLENESS_00CYCLE;
  hspi1.Init.MasterReceiverAutoSusp = SPI_MASTER_RX_AUTOSUSP_DISABLE;
  hspi1.Init.MasterKeepIOState = SPI_MASTER_KEEP_IO_STATE_DISABLE;
  hspi1.Init.IOSwap = SPI_IO_SWAP_DISABLE;
  if (HAL_SPI_Init(&hspi1) != HAL_OK)
  {
    Error_Handler();
  }

}

static void MX_SPI2_Init(void)
{

  /* SPI2 parameter configuration*/
  hspi2.Instance = SPI2;
  hspi2.Init.Mode = SPI_MODE_MASTER;
  hspi2.Init.Direction = SPI_DIRECTION_2LINES;
  hspi2.Init.DataSize = SPI_DATASIZE_4BIT;
  hspi2.Init.CLKPolarity = SPI_POLARITY_LOW;
  hspi2.Init.CLKPhase = SPI_PHASE_1EDGE;
  hspi2.Init.NSS = SPI_NSS_HARD_OUTPUT;
  hspi2.Init.BaudRatePrescaler = SPI_BAUDRATEPRESCALER_2;
  hspi2.Init.FirstBit = SPI_FIRSTBIT_MSB;
  hspi2.Init.TIMode = SPI_TIMODE_DISABLE;
  hspi2.Init.CRCCalculation = SPI_CRCCALCULATION_DISABLE;
  hspi2.Init.CRCPolynomial = 0x0;
  hspi2.Init.NSSPMode = SPI_NSS_PULSE_ENABLE;
  hspi2.Init.NSSPolarity = SPI_NSS_POLARITY_LOW;
  hspi2.Init.FifoThreshold = SPI_FIFO_THRESHOLD_01DATA;
  hspi2.Init.TxCRCInitializationPattern = SPI_CRC_INITIALIZATION_ALL_ZERO_PATTERN;
  hspi2.Init.RxCRCInitializationPattern = SPI_CRC_INITIALIZATION_ALL_ZERO_PATTERN;
  hspi2.Init.MasterSSIdleness = SPI_MASTER_SS_IDLENESS_00CYCLE;
  hspi2.Init.MasterInterDataIdleness = SPI_MASTER_INTERDATA_IDLENESS_00CYCLE;
  hspi2.Init.MasterReceiverAutoSusp = SPI_MASTER_RX_AUTOSUSP_DISABLE;
  hspi2.Init.MasterKeepIOState = SPI_MASTER_KEEP_IO_STATE_DISABLE;
  hspi2.Init.IOSwap = SPI_IO_SWAP_DISABLE;
  if (HAL_SPI_Init(&hspi2) != HAL_OK)
  {
    Error_Handler();
  }

}

static void MX_TIM2_Init(void)
{

  TIM_MasterConfigTypeDef sMasterConfig = {0};
  TIM_OC_InitTypeDef sConfigOC = {0};

  htim2.Instance = TIM2;
  htim2.Init.Prescaler = 68;
  htim2.Init.CounterMode = TIM_COUNTERMODE_UP;
  htim2.Init.Period = 1000;
  htim2.Init.ClockDivision = TIM_CLOCKDIVISION_DIV1;
  htim2.Init.AutoReloadPreload = TIM_AUTORELOAD_PRELOAD_DISABLE;
  if (HAL_TIM_PWM_Init(&htim2) != HAL_OK)
  {
    Error_Handler();
  }
  sMasterConfig.MasterOutputTrigger = TIM_TRGO_RESET;
  sMasterConfig.MasterSlaveMode = TIM_MASTERSLAVEMODE_DISABLE;
  if (HAL_TIMEx_MasterConfigSynchronization(&htim2, &sMasterConfig) != HAL_OK)
  {
    Error_Handler();
  }
  sConfigOC.OCMode = TIM_OCMODE_PWM1;
  sConfigOC.Pulse = 500;
  sConfigOC.OCPolarity = TIM_OCPOLARITY_HIGH;
  sConfigOC.OCFastMode = TIM_OCFAST_DISABLE;
  if (HAL_TIM_PWM_ConfigChannel(&htim2, &sConfigOC, TIM_CHANNEL_3) != HAL_OK)
  {
    Error_Handler();
  }
  HAL_TIM_MspPostInit(&htim2);

}

static void MX_TIM3_Init(void)
{

  TIM_MasterConfigTypeDef sMasterConfig = {0};
  TIM_OC_InitTypeDef sConfigOC = {0};

  htim3.Instance = TIM3;
  htim3.Init.Prescaler = 5;
  htim3.Init.CounterMode = TIM_COUNTERMODE_UP;
  htim3.Init.Period = 1000;
  htim3.Init.ClockDivision = TIM_CLOCKDIVISION_DIV4;
  htim3.Init.AutoReloadPreload = TIM_AUTORELOAD_PRELOAD_ENABLE;
  if (HAL_TIM_PWM_Init(&htim3) != HAL_OK)
  {
    Error_Handler();
  }
  sMasterConfig.MasterOutputTrigger = TIM_TRGO_RESET;
  sMasterConfig.MasterSlaveMode = TIM_MASTERSLAVEMODE_DISABLE;
  if (HAL_TIMEx_MasterConfigSynchronization(&htim3, &sMasterConfig) != HAL_OK)
  {
    Error_Handler();
  }
  sConfigOC.OCMode = TIM_OCMODE_PWM1;
  sConfigOC.Pulse = 5000;
  sConfigOC.OCPolarity = TIM_OCPOLARITY_HIGH;
  sConfigOC.OCFastMode = TIM_OCFAST_DISABLE;
  if (HAL_TIM_PWM_ConfigChannel(&htim3, &sConfigOC, TIM_CHANNEL_3) != HAL_OK)
  {
    Error_Handler();
  }
  HAL_TIM_MspPostInit(&htim3);

}

static void MX_TIM4_Init(void)
{

  TIM_Encoder_InitTypeDef sConfig = {0};
  TIM_MasterConfigTypeDef sMasterConfig = {0};

  htim4.Instance = TIM4;
  htim4.Init.Prescaler = 0;
  htim4.Init.CounterMode = TIM_COUNTERMODE_UP;
  htim4.Init.Period = 65535;
  htim4.Init.ClockDivision = TIM_CLOCKDIVISION_DIV1;
  htim4.Init.AutoReloadPreload = TIM_AUTORELOAD_PRELOAD_DISABLE;
  sConfig.EncoderMode = TIM_ENCODERMODE_TI1;
  sConfig.IC1Polarity = TIM_ICPOLARITY_RISING;
  sConfig.IC1Selection = TIM_ICSELECTION_DIRECTTI;
  sConfig.IC1Prescaler = TIM_ICPSC_DIV1;
  sConfig.IC1Filter = 0;
  sConfig.IC2Polarity = TIM_ICPOLARITY_RISING;
  sConfig.IC2Selection = TIM_ICSELECTION_DIRECTTI;
  sConfig.IC2Prescaler = TIM_ICPSC_DIV1;
  sConfig.IC2Filter = 0;
  if (HAL_TIM_Encoder_Init(&htim4, &sConfig) != HAL_OK)
  {
    Error_Handler();
  }
  sMasterConfig.MasterOutputTrigger = TIM_TRGO_RESET;
  sMasterConfig.MasterSlaveMode = TIM_MASTERSLAVEMODE_DISABLE;
  if (HAL_TIMEx_MasterConfigSynchronization(&htim4, &sMasterConfig) != HAL_OK)
  {
    Error_Handler();
  }

}

static void MX_TIM5_Init(void)
{

  TIM_Encoder_InitTypeDef sConfig = {0};
  TIM_MasterConfigTypeDef sMasterConfig = {0};

  htim5.Instance = TIM5;
  htim5.Init.Prescaler = 0;
  htim5.Init.CounterMode = TIM_COUNTERMODE_UP;
  htim5.Init.Period = 65535;
  htim5.Init.ClockDivision = TIM_CLOCKDIVISION_DIV1;
  htim5.Init.AutoReloadPreload = TIM_AUTORELOAD_PRELOAD_DISABLE;
  sConfig.EncoderMode = TIM_ENCODERMODE_TI1;
  sConfig.IC1Polarity = TIM_ICPOLARITY_RISING;
  sConfig.IC1Selection = TIM_ICSELECTION_DIRECTTI;
  sConfig.IC1Prescaler = TIM_ICPSC_DIV1;
  sConfig.IC1Filter = 0;
  sConfig.IC2Polarity = TIM_ICPOLARITY_RISING;
  sConfig.IC2Selection = TIM_ICSELECTION_DIRECTTI;
  sConfig.IC2Prescaler = TIM_ICPSC_DIV1;
  sConfig.IC2Filter = 0;
  if (HAL_TIM_Encoder_Init(&htim5, &sConfig) != HAL_OK)
  {
    Error_Handler();
  }
  sMasterConfig.MasterOutputTrigger = TIM_TRGO_RESET;
  sMasterConfig.MasterSlaveMode = TIM_MASTERSLAVEMODE_DISABLE;
  if (HAL_TIMEx_MasterConfigSynchronization(&htim5, &sMasterConfig) != HAL_OK)
  {
    Error_Handler();
  }

}

/* FMC initialization function */
static void MX_FMC_Init(void)
{

  FMC_SDRAM_TimingTypeDef SdramTiming = {0};

  /** Perform the SDRAM2 memory initialization sequence
  */
  hsdram2.Instance = FMC_SDRAM_DEVICE;
  /* hsdram2.Init */
  hsdram2.Init.SDBank = FMC_SDRAM_BANK2;
  hsdram2.Init.ColumnBitsNumber = FMC_SDRAM_COLUMN_BITS_NUM_8;
  hsdram2.Init.RowBitsNumber = FMC_SDRAM_ROW_BITS_NUM_12;
  hsdram2.Init.MemoryDataWidth = FMC_SDRAM_MEM_BUS_WIDTH_16;
  hsdram2.Init.InternalBankNumber = FMC_SDRAM_INTERN_BANKS_NUM_4;
  hsdram2.Init.CASLatency = FMC_SDRAM_CAS_LATENCY_3;
  hsdram2.Init.WriteProtection = FMC_SDRAM_WRITE_PROTECTION_DISABLE;
  hsdram2.Init.SDClockPeriod = FMC_SDRAM_CLOCK_PERIOD_2;
  hsdram2.Init.ReadBurst = FMC_SDRAM_RBURST_ENABLE;
  hsdram2.Init.ReadPipeDelay = FMC_SDRAM_RPIPE_DELAY_1;
  /* SdramTiming */
  SdramTiming.LoadToActiveDelay = 2;
  SdramTiming.ExitSelfRefreshDelay = 14;
  SdramTiming.SelfRefreshTime = 8;
  SdramTiming.RowCycleDelay = 11;
  SdramTiming.WriteRecoveryTime = 5;
  SdramTiming.RPDelay = 3;
  SdramTiming.RCDDelay = 3;

  if (HAL_SDRAM_Init(&hsdram2, &SdramTiming) != HAL_OK)
  {
    Error_Handler( );
  }

  /* USER CODE BEGIN FMC_Init 2 */
	_sdram_Init.PtrSDRAMHanldeTypeDef = &hsdram2;
	_sdram_Init.TargetBank      = FMC_SDRAM_CMD_TARGET_BANK2		;
	_sdram_Init.RefreshMode     = _SDRAM_AUTOREFRESH_MODE_CMD		;
	_sdram_Init.RefreshRate     = ((uint32_t)0x0fa0)   				;
	_sdram_Init.BurstLength     = _SDRAM_BURST_LENGTH_8				;
	_sdram_Init.BurstType       = _SDRAM_BURST_TYPE_SEQUENTIAL		;
	_sdram_Init.CASLatency      = _SDRAM_CAS_LATENCY_3				;
	_sdram_Init.OperationMode   = _SDRAM_OPERATING_MODE_STANDARD	;
	_sdram_Init.WriteBurstMode  = _SDRAM_WRITEBURST_MODE_SINGLE		;
	_sdram_InitModule();

  /* USER CODE END FMC_Init 2 */
}

static void MX_GPIO_Init(void)
{
  GPIO_InitTypeDef GPIO_InitStruct = {0};

  /* GPIO Ports Clock Enable */
  __HAL_RCC_GPIOC_CLK_ENABLE();
  __HAL_RCC_GPIOF_CLK_ENABLE();
  __HAL_RCC_GPIOH_CLK_ENABLE();
  __HAL_RCC_GPIOA_CLK_ENABLE();
  __HAL_RCC_GPIOB_CLK_ENABLE();
  __HAL_RCC_GPIOG_CLK_ENABLE();
  __HAL_RCC_GPIOE_CLK_ENABLE();
  __HAL_RCC_GPIOD_CLK_ENABLE();

  /*Configure GPIO pin Output Level */
  HAL_GPIO_WritePin(GPIOF, GPIO_PIN_6, GPIO_PIN_RESET);

  /*Configure GPIO pin Output Level */
  HAL_GPIO_WritePin(LTDC_PIN31_GPIO_Port, LTDC_PIN31_Pin, GPIO_PIN_RESET);

  /*Configure GPIO pin Output Level */
  HAL_GPIO_WritePin(GPIOC, GPIO_PIN_10|LTDC_PIN35_Pin, GPIO_PIN_RESET);

  /*Configure GPIO pin Output Level */
  HAL_GPIO_WritePin(GPIOD, LED_1_Pin|LED_2_Pin, GPIO_PIN_RESET);

  /*Configure GPIO pin Output Level */
  HAL_GPIO_WritePin(GPIOG, SPI1_CS_Pin|USB_PWN_ON_Pin, GPIO_PIN_SET);

  /*Configure GPIO pin : PF6 */
  GPIO_InitStruct.Pin = GPIO_PIN_6;
  GPIO_InitStruct.Mode = GPIO_MODE_OUTPUT_PP;
  GPIO_InitStruct.Pull = GPIO_NOPULL;
  GPIO_InitStruct.Speed = GPIO_SPEED_FREQ_LOW;
  HAL_GPIO_Init(GPIOF, &GPIO_InitStruct);

  /*Configure GPIO pin : PF7 */
  GPIO_InitStruct.Pin = GPIO_PIN_7;
  GPIO_InitStruct.Mode = GPIO_MODE_AF_PP;
  GPIO_InitStruct.Pull = GPIO_NOPULL;
  GPIO_InitStruct.Speed = GPIO_SPEED_FREQ_VERY_HIGH;
  GPIO_InitStruct.Alternate = GPIO_AF10_OCTOSPIM_P1;
  HAL_GPIO_Init(GPIOF, &GPIO_InitStruct);

  /*Configure GPIO pin : ENCODERCC_P_Pin */
  GPIO_InitStruct.Pin = ENCODERCC_P_Pin;
  GPIO_InitStruct.Mode = GPIO_MODE_INPUT;
  GPIO_InitStruct.Pull = GPIO_NOPULL;
  HAL_GPIO_Init(ENCODERCC_P_GPIO_Port, &GPIO_InitStruct);

  /*Configure GPIO pins : ENCODERSX_P_Pin PULSRETRO_Pin */
  GPIO_InitStruct.Pin = ENCODERSX_P_Pin|PULSRETRO_Pin;
  GPIO_InitStruct.Mode = GPIO_MODE_INPUT;
  GPIO_InitStruct.Pull = GPIO_NOPULL;
  HAL_GPIO_Init(GPIOD, &GPIO_InitStruct);

  /*Configure GPIO pin : ENCODERDX_P_Pin */
  GPIO_InitStruct.Pin = ENCODERDX_P_Pin;
  GPIO_InitStruct.Mode = GPIO_MODE_INPUT;
  GPIO_InitStruct.Pull = GPIO_NOPULL;
  HAL_GPIO_Init(ENCODERDX_P_GPIO_Port, &GPIO_InitStruct);

  /*Configure GPIO pin : LTDC_PIN31_Pin */
  GPIO_InitStruct.Pin = LTDC_PIN31_Pin;
  GPIO_InitStruct.Mode = GPIO_MODE_OUTPUT_PP;
  GPIO_InitStruct.Pull = GPIO_NOPULL;
  GPIO_InitStruct.Speed = GPIO_SPEED_FREQ_LOW;
  HAL_GPIO_Init(LTDC_PIN31_GPIO_Port, &GPIO_InitStruct);

  /*Configure GPIO pin : PA9 */
  GPIO_InitStruct.Pin = GPIO_PIN_9;
  GPIO_InitStruct.Mode = GPIO_MODE_INPUT;
  GPIO_InitStruct.Pull = GPIO_NOPULL;
  HAL_GPIO_Init(GPIOA, &GPIO_InitStruct);

  /*Configure GPIO pins : PC10 LTDC_PIN35_Pin */
  GPIO_InitStruct.Pin = GPIO_PIN_10|LTDC_PIN35_Pin;
  GPIO_InitStruct.Mode = GPIO_MODE_OUTPUT_PP;
  GPIO_InitStruct.Pull = GPIO_NOPULL;
  GPIO_InitStruct.Speed = GPIO_SPEED_FREQ_LOW;
  HAL_GPIO_Init(GPIOC, &GPIO_InitStruct);

  /*Configure GPIO pins : LED_1_Pin LED_2_Pin */
  GPIO_InitStruct.Pin = LED_1_Pin|LED_2_Pin;
  GPIO_InitStruct.Mode = GPIO_MODE_OUTPUT_PP;
  GPIO_InitStruct.Pull = GPIO_NOPULL;
  GPIO_InitStruct.Speed = GPIO_SPEED_FREQ_LOW;
  HAL_GPIO_Init(GPIOD, &GPIO_InitStruct);

  /*Configure GPIO pins : SPI1_CS_Pin USB_PWN_ON_Pin */
  GPIO_InitStruct.Pin = SPI1_CS_Pin|USB_PWN_ON_Pin;
  GPIO_InitStruct.Mode = GPIO_MODE_OUTPUT_OD;
  GPIO_InitStruct.Pull = GPIO_NOPULL;
  GPIO_InitStruct.Speed = GPIO_SPEED_FREQ_LOW;
  HAL_GPIO_Init(GPIOG, &GPIO_InitStruct);

}

/* USER CODE BEGIN 4 */
// Usato per debuggare
/* USER CODE END 4 */

void StartDefaultTask(void *argument)
{
  /* init code for USB_HOST */
  MX_USB_HOST_Init();
  for(;;)
  {
	  osDelay(1);
  }
}

 /* MPU Configuration */

void MPU_Config(void)
{
  MPU_Region_InitTypeDef MPU_InitStruct = {0};

  /* Disables the MPU */
  HAL_MPU_Disable();

  /** Initializes and configures the Region and the memory to be protected
  */
  MPU_InitStruct.Enable = MPU_REGION_ENABLE;
  MPU_InitStruct.Number = MPU_REGION_NUMBER1;
  MPU_InitStruct.BaseAddress = 0x90000000;
  MPU_InitStruct.Size = MPU_REGION_SIZE_32MB;
  MPU_InitStruct.SubRegionDisable = 0x0;
  MPU_InitStruct.TypeExtField = MPU_TEX_LEVEL0;
  MPU_InitStruct.AccessPermission = MPU_REGION_FULL_ACCESS;
  MPU_InitStruct.DisableExec = MPU_INSTRUCTION_ACCESS_ENABLE;
  MPU_InitStruct.IsShareable = MPU_ACCESS_SHAREABLE;
  MPU_InitStruct.IsCacheable = MPU_ACCESS_CACHEABLE;
  MPU_InitStruct.IsBufferable = MPU_ACCESS_BUFFERABLE;

  HAL_MPU_ConfigRegion(&MPU_InitStruct);

  /** Initializes and configures the Region and the memory to be protected
  */
  MPU_InitStruct.Number = MPU_REGION_NUMBER2;
  MPU_InitStruct.BaseAddress = 0xd0000000;
  MPU_InitStruct.Size = MPU_REGION_SIZE_8MB;
  MPU_InitStruct.DisableExec = MPU_INSTRUCTION_ACCESS_DISABLE;
  MPU_InitStruct.IsShareable = MPU_ACCESS_NOT_SHAREABLE;

  HAL_MPU_ConfigRegion(&MPU_InitStruct);
  /* Enables the MPU */
  HAL_MPU_Enable(MPU_PRIVILEGED_DEFAULT);

}

void HAL_TIM_PeriodElapsedCallback(TIM_HandleTypeDef *htim)
{
  /* USER CODE BEGIN Callback 0 */
	if(htim->Instance == TIM6)
	{
		HAL_IncTick();
		swtimer_Manager1MS();
		applicazione_Manager1MS();
		//niknik tgfxcustom_Manager1MS();
	}
#if(0)
  /* USER CODE END Callback 0 */
  if (htim->Instance == TIM6) {
    HAL_IncTick();
  }
  /* USER CODE BEGIN Callback 1 */
#endif
  /* USER CODE END Callback 1 */
}

void Error_Handler(void)
{
  __disable_irq();
  while (1)
  {
  }
}

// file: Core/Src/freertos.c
/* USER CODE BEGIN Header */
/**
  ******************************************************************************
  * File Name          : freertos.c
  * Description        : Code for freertos applications
  ******************************************************************************
  * @attention
  *
  * Copyright (c) 2023 STMicroelectronics.
  * All rights reserved.
  *
  * This software is licensed under terms that can be found in the LICENSE file
  * in the root directory of this software component.
  * If no LICENSE file comes with this software, it is provided AS-IS.
  *
  ******************************************************************************
  */
/* USER CODE END Header */

#include "FreeRTOS.h"
#include "task.h"
#include "main.h"

/* Hook prototypes */
void vApplicationIdleHook(void);
void vApplicationStackOverflowHook(xTaskHandle xTask, signed char *pcTaskName);

/* USER CODE BEGIN 2 */
void vApplicationIdleHook( void )
{
   /* vApplicationIdleHook() will only be called if configUSE_IDLE_HOOK is set
   to 1 in FreeRTOSConfig.h. It will be called on each iteration of the idle
   task. It is essential that code added to this hook function never attempts
   to block in any way (for example, call xQueueReceive() with a block time
   specified, or call vTaskDelay()). If the application makes use of the
   vTaskDelete() API function (as this demo application does) then it is also
   important that vApplicationIdleHook() is permitted to return to its calling
   function, because it is the responsibility of the idle task to clean up
   memory allocated by the kernel to any task that has since been deleted. */
}
/* USER CODE END 2 */

/* USER CODE BEGIN 4 */
void vApplicationStackOverflowHook(xTaskHandle xTask, signed char *pcTaskName)
{
   /* Run time stack overflow checking is performed if
   configCHECK_FOR_STACK_OVERFLOW is defined to 1 or 2. This hook function is
   called if a stack overflow is detected. */
}
/* USER CODE END 4 */
